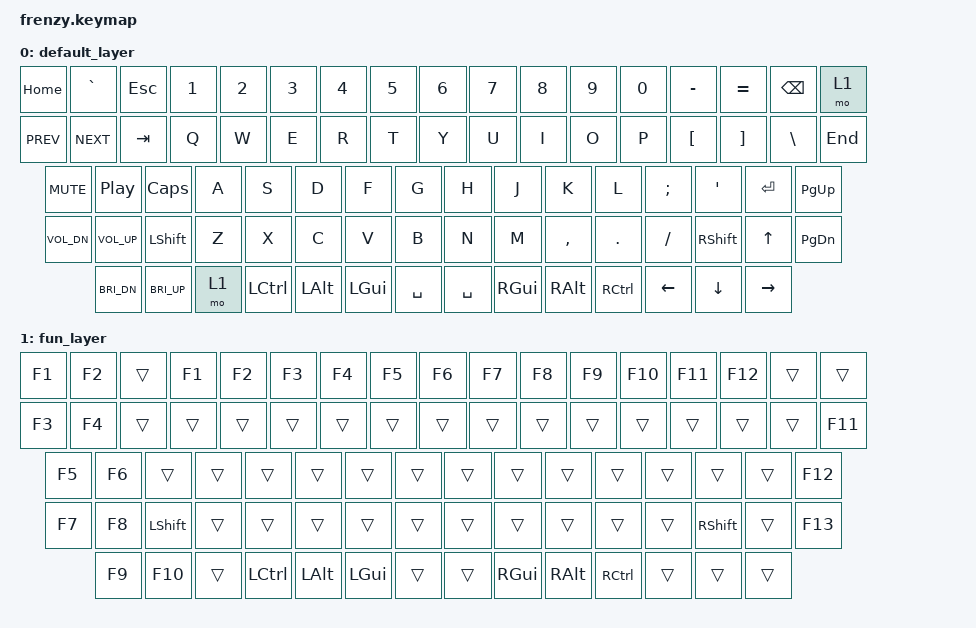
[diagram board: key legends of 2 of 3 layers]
/*
 * Copyright (c) 2020 The ZMK Contributors
 *
 * SPDX-License-Identifier: MIT
 */

#include <behaviors.dtsi>
#include <dt-bindings/zmk/bt.h>
#include <dt-bindings/zmk/keys.h>

/ {
    keymap {
        compatible = "zmk,keymap";

// ---------------------------------------------------------------------------------------------------------------------
// | HOME| `   |  ESC  |  1   |  2  |  3   |  4  |  5  |  6  |      |  7  |  8  |  9  |  0  |  -  |  =  |  BKSPC | FN   |
// | PREV| NEXT|  TAB   |  Q   |  W  |  E   |  R  |  T  |        |  Y  |  U  |  I  |  O  |  P  |  [  |  ]  |  \  | END  |
// | MUTE| PLAY|  CAPS   |  A   |  S  |  D   |  F  |  G  |        |  H  |  J  |  K  |  L  |  ;  |  '  |   ENTER  | PGUP |
// | VOLD| VOLU|  SHIFT   |  Z   |  X  |  C  |  V   |  B  |        |  N  |  M  |  ,  |  .  |  /  |  RSHFT  |  UP | PGDN |
// | BRID| BRIU|  FN    | LCTRL   | LALT | LGUI  |   SPACE   |    |    SPACE   | RGUI | RALT | RCTRL | LFT | DWN | RGHT |
// ---------------------------------------------------------------------------------------------------------------------

        default_layer {
            bindings = <
    &kp HOME    &kp GRAVE    &kp ESC &kp N1     &kp N2   &kp N3    &kp N4 &kp N5 &kp N6   /**/ &kp N7      &kp N8   &kp N9    &kp N0    &kp MINUS &kp EQUAL &kp BSPC &mo 1 
    &kp C_PREV   &kp C_NEXT   &kp TAB   &kp Q      &kp W    &kp E     &kp R  &kp T           /**/ &kp Y       &kp U    &kp I     &kp O     &kp P     &kp LBKT  &kp RBKT &kp BSLH &kp END
    &kp K_MUTE   &kp C_PP     &kp CAPS   &kp A      &kp S    &kp D     &kp F  &kp G           /**/ &kp H       &kp J    &kp K     &kp L     &kp SEMI  &kp SQT   &kp RET  &kp PG_UP
    &kp C_VOL_DN &kp C_VOL_UP &kp LSHFT &kp Z      &kp X    &kp C     &kp V  &kp B           /**/ &kp N       &kp M    &kp COMMA &kp DOT   &kp FSLH  &kp RSHFT &kp UP   &kp PG_DN
    &kp C_BRI_DN &kp C_BRI_UP &mo 1  &kp LCTRL &kp LALT &kp LGUI  &kp SPACE             /**/ &kp SPACE &kp RGUI &kp RALT  &kp RCTRL &kp LEFT  &kp DOWN  &kp RIGHT
            >;
        };

// ---------------------------------------------------------------------------------------------------------------------
// | F1  | F2  |       |  F1  | F2  | F3   | F4  | F5  | F6  |      | F7  | F8  | F9  | F10 | F11 | F12 |        |      |
// | F3  | F4  |        |      |     |      |     |     |        |     |     |     |     |     |     |     |     | F11  |
// | F5  | F6  |         |      |     |      |     |     |        |     |     |    |      |     |     |          | F12  |
// | F7  | F8  |  SHIFT   |      |     |     |      |     |        |     |     |     |     |     | RSHIFT  |     | F13  |
// | F9  | F10 |          | LCTRL   | LALT | LGUI  |       |      |            | RGUI | RALT | RCTRL |     |     |      |
// ---------------------------------------------------------------------------------------------------------------------

        fun_layer {
            bindings = <
    &kp F1 &kp F2 &trans &kp F1  &kp F2   &kp F3 &kp F4 &kp F5  &kp F6    /**/ &kp F7     &kp F8     &kp F9   &kp F10   &kp F11      &kp F12      &trans      &trans
    &kp F3 &kp F4 &trans &trans  &trans   &trans &trans &trans            /**/ &trans  &trans  &trans &trans    &trans  &trans       &trans &trans &kp F11
    &kp F5 &kp F6 &trans &trans  &trans   &trans &trans &trans            /**/ &trans   &trans    &trans    &trans &trans       &trans       &trans      &kp F12
    &kp F7 &kp F8 &kp LSHIFT &trans  &trans  &trans &trans &trans            /**/ &trans     &trans     &trans   &trans    &trans       &kp RSHFT        &trans  &kp F13
    &kp F9 &kp F10 &trans &kp LCTRL &kp LALT &kp LGUI &trans           /**/ &trans              &kp RGUI &kp RALT  &kp RCTRL       &trans &trans &trans
            >;
        };

// ---------------------------------------------------------------------------------------------------------------------
// |     |     |       |      |     |      |     |     |     |      |     |     |     |     |     |     |  BKSPC |      |
// |     |     |        |      |     |      |     |     |        |     |  7  |  8  |  9  |  -  |     |     |     |      |
// |     |     |         |      |     |      |     |     |        |     |  4  | 5   |  6  |  +  |     | ENTER    |      |
// |     |     |          |      |     |     |      |     |        |     |  1  |  2  |  3  |  =  |         |     |      |
// |     |     |          |    |      |       |   TAB      |      |      0     |  .   |ENTER |       |     |     |      |
// ---------------------------------------------------------------------------------------------------------------------

        num_layer {
            bindings = <
    &trans &trans &trans &trans &trans &trans &trans &trans &trans  /**/ &trans  &trans  &trans   &trans   &trans     &trans &kp BSPC &trans
    &trans &trans &trans &trans &trans &trans &trans &trans         /**/ &trans  &kp N7  &kp N8   &kp N9   &kp MINUS  &trans &trans  &trans &trans
    &trans &trans &trans &trans &trans &trans &trans &trans         /**/ &trans  &kp N4  &kp N5   &kp N6   &kp PLUS   &trans &kp RET &trans
    &trans &trans &trans &trans &trans &trans &trans &trans         /**/ &trans  &kp N1  &kp N2   &kp N3   &kp EQUAL  &trans &trans  &trans
    &trans &trans &trans &trans &trans &trans &trans &kp TAB        /**/ &kp N0          &kp DOT  &kp RET  &trans     &trans &trans  &trans
            >;
        };

// ---------------------------------------------------------------------------------------------------------------------
// |     |     |       |      |     |      |     |     |     |      |     |     |     |     |     |     |        |      |
// |     |     |        |      |     |      |     |     |        |     |     |     |     |     |     |     |     |      |
// |     |     |         |      |     |      |     |     |        |     |     |     |     |     |     |          |      |
// |     |     |          |      |     |     |      |     |        |     |     |     |     |     |         |     |      |
// |     |     |          |    |      |       |            |      |            |      |      |       |     |     |      |
// ---------------------------------------------------------------------------------------------------------------------

    };
};

